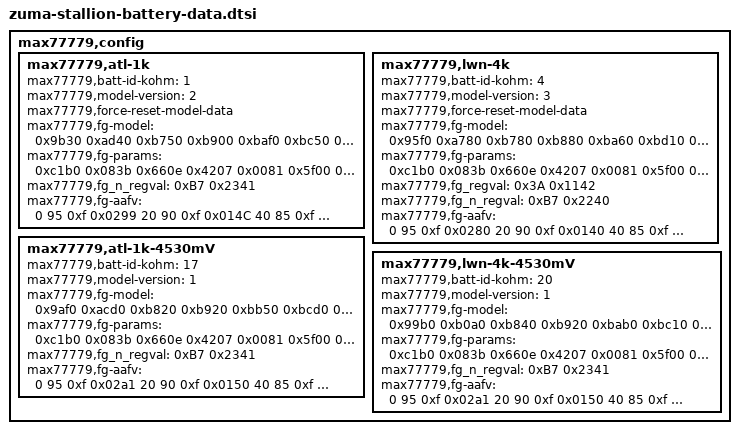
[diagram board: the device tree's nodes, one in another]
// SPDX-License-Identifier: GPL-2.0-only
/*
 * Battery device tree entries
 *
 * Copyright 2024 Google LLC
 *
 */

max77779,config {

	/* STA5_ATL_3837_G1.ini.txt, b/394419666#comment1 */
	max77779,atl-1k {
		max77779,batt-id-kohm = <1>;
		max77779,model-version = <2>;
		max77779,force-reset-model-data;
		max77779,fg-model = /bits/ 16 <
			0x9b30 0xad40 0xb750 0xb900 0xbaf0 0xbc50 0xbd70 0xbf00
			0xc260 0xc620 0xcb80 0xcc70 0xd040 0xd420 0xd980 0xdf00
			0x0040 0x0180 0x0f00 0x0dc0 0x10d0 0x1180 0x1880 0x0f10
			0x0790 0x07f0 0x0610 0x06c0 0x06d0 0x06f0 0x0570 0x0570
		>;
		max77779,fg-params = /bits/ 16 <
			/* 0x00C0 */	0xc1b0	/* nNVCfg0 */
			/* 0x00B6 */	0x083b	/* RelaxCFG */
			/* 0x009F */	0x660e	/* nLearnCFG */
			/* 0x000C */	0x4207	/* Config */
			/* 0x00AB */	0x0081	/* Config2 */
			/* 0x00BC */	0x5f00	/* nFullSOCthr */
			/* 0x00A9 */	0x081d	/* nFullCAPRep */
			/* 0x00B3 */	0x081d	/* nDesignCap */
			/* 0x0046 */	0x0C80	/* dPacc */
			/* 0x00A5 */	0x081d	/* nFullCAPNom */
			/* 0x00C6 */	0xa55a	/* nV_empty */
			/* 0x00A0 */	0x3708	/* nQRTable00 */
			/* 0x00A1 */	0x1882	/* nQRTable10 */
			/* 0x00A2 */	0x0902	/* nQRTable20 */
			/* 0x00A3 */	0x0682	/* nQRTable30 */
			/* 0x00A6 */	0x05c0	/* nRCOMP0 */
			/* 0x00A7 */	0x0d02	/* nTempCo */
			/* 0x009C */	0x0299	/* nIChgTerm */
			/* 0x00B2 */	0x3870	/* nMiscCFG */
			/* 0x009E */	0x0400	/* nModelCfg */
			/* 0x00CA */	0xC8FF	/* nThermCfg */
			/* 0x009D */	0xCEA4	/* nFilterCfg */
		>;
		max77779,fg_n_regval = /bits/ 16 <
			0xB7 0x2341	/* nConvgCfg */
		>;
		max77779,fg-aafv = /bits/ 32 <
			  0   95  0xf  0x0299
			 20   90  0xf  0x014C
			 40   85  0xf  0x014C
			 60   80  0xf  0x014C
			 80   75  0xf  0x014C
			120   70  0xf  0x014C
		>;
	};

	/* STA5_LWN_3953_G1.txt, b/441795849#comment1 */
	max77779,lwn-4k {
		max77779,batt-id-kohm = <4>;
		max77779,model-version = <3>;
		max77779,force-reset-model-data;
		max77779,fg-model = /bits/ 16 <
			0x95f0 0xa780 0xb780 0xb880 0xba60 0xbd10 0xc000 0xc2d0
			0xc660 0xca00 0xcdd0 0xd0a0 0xd530 0xd8a0 0xdbd0 0xdf00
			0x0020 0x00f0 0x14e0 0x0d10 0x1120 0x1140 0x0f10 0x0730
			0x06f0 0x06d0 0x0700 0x0640 0x06e0 0x07f0 0x0730 0x0730
		>;
		max77779,fg-params = /bits/ 16 <
			/* 0x00C0 */	0xc1b0	/* nnvcfg0 */
			/* 0x00B6 */	0x083b	/* nrelaxcfg */
			/* 0x009F */	0x660e	/* nLearnCFG */
			/* 0x000C */	0x4207	/* Config */
			/* 0x00AB */	0x0081	/* Config2 */
			/* 0x00BC */	0x5f00	/* nFullSOCThr */
			/* 0x00A9 */	0x0834	/* nfullcaprep */
			/* 0x00B3 */	0x0834	/* ndesigncap */
			/* 0x0046 */	0x0c80	/* dPacc */
			/* 0x00A5 */	0x0834	/* nfullcapnom */
			/* 0x00C6 */	0xa55a	/* nVEmpty */
			/* 0x00A0 */	0x1f0c	/* nQRTable00 */
			/* 0x00A1 */	0x1109	/* nQRTable10 */
			/* 0x00A2 */	0x0a81	/* nQRTable20 */
			/* 0x00A3 */	0x0881	/* nQRTable30 */
			/* 0x00A6 */	0x06b0	/* nRCOMP0 */
			/* 0x00A7 */	0x2002	/* nTempCo */
			/* 0x009C */	0x0280	/* nichgterm */
			/* 0x00B2 */	0x3870	/* nmisccfg */
			/* 0x009E */	0x0400	/* nModelCfg */
			/* 0x00CA */	0xc8ff	/* nThermCfg */
			/* 0x009D */	0xcea4	/* nFilterCfg */
		>;
		max77779,fg_regval = /bits/ 16 <
			0x3A 0x1142    /* SOCHold */
		>;
		max77779,fg_n_regval = /bits/ 16 <
			0xB7 0x2240	/* nConvgCfg */
		>;
		max77779,fg-aafv = /bits/ 32 <
			  0   95  0xf  0x0280
			 20   90  0xf  0x0140
			 40   85  0xf  0x0140
			 60   80  0xf  0x0140
			 80   75  0xf  0x0140
			120   70  0xf  0x0140
		>;
	};

	/* STA5DOE2_ATL_3850_G1.ini.txt, b/399741553#comment1 */
	max77779,atl-1k-4530mV {
		max77779,batt-id-kohm = <17>;
		max77779,model-version = <1>;
		max77779,fg-model = /bits/ 16 <
			0x9af0 0xacd0 0xb820 0xb920 0xbb50 0xbcd0 0xbe60 0xbfc0
			0xc2a0 0xc4b0 0xc7d0 0xcb30 0xce70 0xd430 0xdc90 0xdff0
			0x0050 0x0120 0x1c40 0x0c40 0x0ff0 0x14d0 0x1630 0x0e10
			0x0730 0x0760 0x07d0 0x06e0 0x0660 0x06e0 0x04a0 0x04a0
		>;
		max77779,fg-params = /bits/ 16 <
			/* 0x00C0 */	0xc1b0	/* nnvcfg0 */
			/* 0x00B6 */	0x083b	/* nrelaxcfg */
			/* 0x009F */	0x660e	/* nLearnCFG */
			/* 0x000C */	0x4207	/* Config */
			/* 0x00AB */	0x0081	/* Config2 */
			/* 0x00BC */	0x5f00	/* nFullSOCThr */
			/* 0x00A9 */	0x0832	/* nfullcaprep */
			/* 0x00B3 */	0x0832	/* ndesigncap */
			/* 0x0046 */	0x0c80	/* dPacc */
			/* 0x00A5 */	0x0832	/* nfullcapnom */
			/* 0x00C6 */	0xa55a	/* nVEmpty */
			/* 0x00A0 */	0x2296	/* nQRTable00 */
			/* 0x00A1 */	0x140a	/* nQRTable10 */
			/* 0x00A2 */	0x0d00	/* nQRTable20 */
			/* 0x00A3 */	0x0900	/* nQRTable30 */
			/* 0x00A6 */	0x0500	/* nRCOMP0 */
			/* 0x00A7 */	0x0c02	/* nTempCo */
			/* 0x009C */	0x02a1	/* nichgterm */
			/* 0x00B2 */	0x3870	/* nmisccfg */
			/* 0x009E */	0x0400	/* nModelCfg */
			/* 0x00CA */	0xc8ff	/* nThermCfg */
			/* 0x009D */	0xcea4	/* nFilterCfg */
		>;
		max77779,fg_n_regval = /bits/ 16 <
			0xB7 0x2341	/* nConvgCfg */
		>;
		max77779,fg-aafv = /bits/ 32 <
			  0   95  0xf  0x02a1
			 20   90  0xf  0x0150
			 40   85  0xf  0x0150
			 60   80  0xf  0x0150
			 80   75  0xf  0x0150
			120   70  0xf  0x0150
		>;
	};

	/* STA5DOE2_LWN_3851_G1.ini.txt, b/399740320#comment1 */
	max77779,lwn-4k-4530mV {
		max77779,batt-id-kohm = <20>;
		max77779,model-version = <1>;
		max77779,fg-model = /bits/ 16 <
			0x99b0 0xb0a0 0xb840 0xb920 0xbab0 0xbc10 0xbda0 0xc170
			0xc420 0xc770 0xcbd0 0xd1e0 0xd590 0xd9a0 0xdd70 0xe050
			0x0050 0x01d0 0x1cf0 0x0b10 0x1170 0x10a0 0x11c0 0x0aa0
			0x05a0 0x0770 0x0680 0x06a0 0x06a0 0x0780 0x0570 0x0570
		>;
		max77779,fg-params = /bits/ 16 <
			/* 0x00C0 */	0xc1b0	/* nnvcfg0 */
			/* 0x00B6 */	0x083b	/* nrelaxcfg */
			/* 0x009F */	0x660e	/* nLearnCFG */
			/* 0x000C */	0x4207	/* Config */
			/* 0x00AB */	0x0081	/* Config2 */
			/* 0x00BC */	0x5f00	/* nFullSOCThr */
			/* 0x00A9 */	0x0839	/* nfullcaprep */
			/* 0x00B3 */	0x0839	/* ndesigncap */
			/* 0x0046 */	0x0c80	/* dPacc */
			/* 0x00A5 */	0x0839	/* nfullcapnom */
			/* 0x00C6 */	0xa55a	/* nVEmpty */
			/* 0x00A0 */	0x1b1e	/* nQRTable00 */
			/* 0x00A1 */	0x1410	/* nQRTable10 */
			/* 0x00A2 */	0x1104	/* nQRTable20 */
			/* 0x00A3 */	0x0b02	/* nQRTable30 */
			/* 0x00A6 */	0x0560	/* nRCOMP0 */
			/* 0x00A7 */	0x0e02	/* nTempCo */
			/* 0x009C */	0x02a1	/* nichgterm */
			/* 0x00B2 */	0x3870	/* nmisccfg */
			/* 0x009E */	0x0400	/* nModelCfg */
			/* 0x00CA */	0xc8ff	/* nThermCfg */
			/* 0x009D */	0xcea4	/* nFilterCfg */
		>;
		max77779,fg_n_regval = /bits/ 16 <
			0xB7 0x2341	/* nConvgCfg */
		>;
		max77779,fg-aafv = /bits/ 32 <
			  0   95  0xf  0x02a1
			 20   90  0xf  0x0150
			 40   85  0xf  0x0150
			 60   80  0xf  0x0150
			 80   75  0xf  0x0150
			120   70  0xf  0x0150
		>;
	};
};
